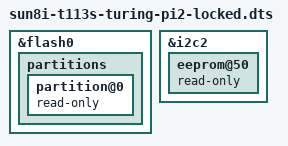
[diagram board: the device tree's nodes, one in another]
// SPDX-License-Identifier: GPL-2.0+
// Copyright (C) 2024 Sven Rademakers <sven@turingpi.com>

/dts-v1/;
/plugin/;

/ {
    fragment@0 {
        target = <&flash0>;

        __overlay__ {
            partitions {
                partition@0 {
                    read-only;
                };
            };
        };
    };

    fragment@1 {
        target = <&i2c2>;
        __overlay__ {
            eeprom@50 {
                read-only;
            };
        };
    };
};
